# STM32H7P5xx register map
File version: 1.0
Registers are 32-bit, read-write, reset 0x0 unless marked. A register's access mark holds for its fields unless they carry their own. Offsets are from the block's base; [hi:lo] are bit positions.

## DAC1 — Digital to Analog Converter (DAC)
Base 0x48027000
Same registers: DAC2 0x48027400, DAC3 0x48027800, DAC4 0x48027C00
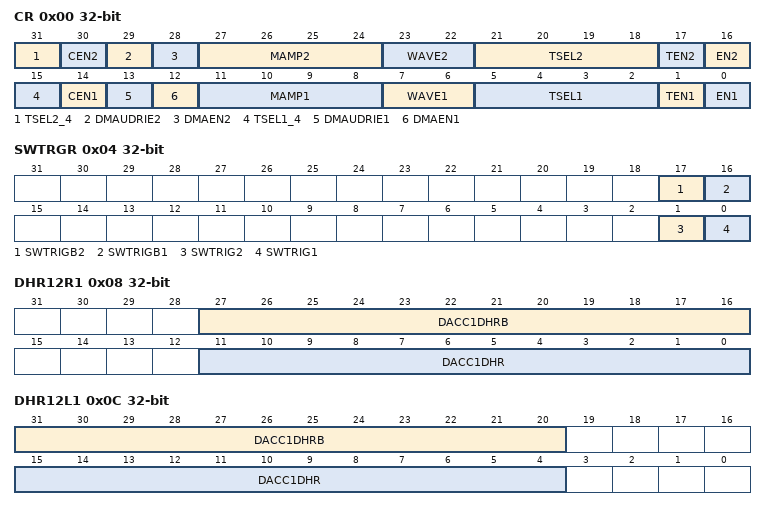
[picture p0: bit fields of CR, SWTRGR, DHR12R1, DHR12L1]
0x00 CR — DAC control register
  [31] TSEL2_4
  [30] CEN2 — DAC channel2 calibration enable
  [29] DMAUDRIE2 — DAC channel2 DMA underrun interrupt enable
  [28] DMAEN2 — DAC channel2 DMA enable
  [27:24] MAMP2 — DAC channel2 mask/amplitude selector
  [23:22] WAVE2 — DAC channel2 noise/triangle wave generation enable
  [21:18] TSEL2 — TSEL2[3:0]: DAC channel2 trigger selection
  [17] TEN2 — DAC channel2 trigger enable
  [16] EN2 — DAC channel2 enable
  [15] TSEL1_4
  [14] CEN1 — DAC channel1 calibration enable
  [13] DMAUDRIE1 — DAC channel1 DMA Underrun Interrupt enable
  [12] DMAEN1 — DAC channel1 DMA enable
  [11:8] MAMP1 — DAC channel1 mask/amplitude selector
  [7:6] WAVE1 — DAC channel1 noise/triangle wave generation enable
  [5:2] TSEL1 — TSEL1[3:0]: DAC channel1 trigger selection
  [1] TEN1 — DAC channel1 trigger enable
  [0] EN1 — DAC channel1 enable
0x04 SWTRGR — DAC software trigger register
  [17] SWTRIGB2 — DAC channel2 software trigger B
  [16] SWTRIGB1 — DAC channel1 software trigger B
  [1] SWTRIG2 — DAC channel2 software trigger
  [0] SWTRIG1 — DAC channel1 software trigger
0x08 DHR12R1 — DAC channel1 12-bit right-aligned data holding register
  [27:16] DACC1DHRB — DAC channel1 12-bit right-aligned data B
  [11:0] DACC1DHR — DAC channel1 12-bit right-aligned data
0x0C DHR12L1 — DAC channel1 12-bit left aligned data holding register
  [31:20] DACC1DHRB — DAC channel1 12-bit left-aligned data B
  [15:4] DACC1DHR — DAC channel1 12-bit left-aligned data
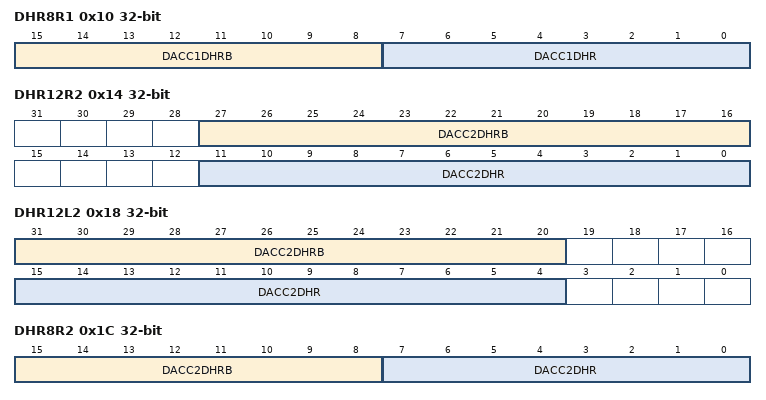
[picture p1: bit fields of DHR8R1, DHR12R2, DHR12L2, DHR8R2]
0x10 DHR8R1 — DAC channel1 8-bit right aligned data holding register
  [15:8] DACC1DHRB — DAC channel1 8-bit right-aligned data
  [7:0] DACC1DHR — DAC channel1 8-bit right-aligned data
0x14 DHR12R2 — DAC channel2 12-bit right aligned data holding register
  [27:16] DACC2DHRB — DAC channel2 12-bit right-aligned data
  [11:0] DACC2DHR — DAC channel2 12-bit right-aligned data
0x18 DHR12L2 — DAC channel2 12-bit left aligned data holding register
  [31:20] DACC2DHRB — DAC channel2 12-bit left-aligned data B
  [15:4] DACC2DHR — DAC channel2 12-bit left-aligned data
0x1C DHR8R2 — DAC channel2 8-bit right-aligned data holding register
  [15:8] DACC2DHRB — DAC channel2 8-bit right-aligned data
  [7:0] DACC2DHR — DAC channel2 8-bit right-aligned data
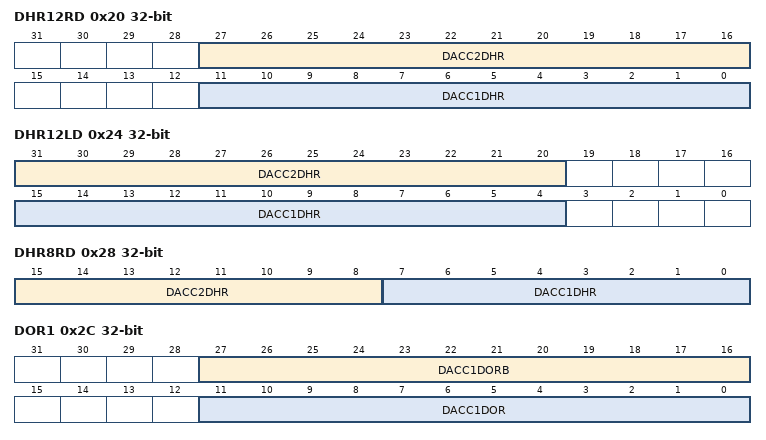
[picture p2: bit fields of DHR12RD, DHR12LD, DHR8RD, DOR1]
0x20 DHR12RD — Dual DAC 12-bit right-aligned data holding register
  [27:16] DACC2DHR — DAC channel2 12-bit right-aligned data
  [11:0] DACC1DHR — DAC channel1 12-bit right-aligned data
0x24 DHR12LD — Dual DAC 12-bit left aligned data holding register
  [31:20] DACC2DHR — DAC channel2 12-bit left-aligned data
  [15:4] DACC1DHR — DAC channel1 12-bit left-aligned data
0x28 DHR8RD — Dual DAC 8-bit right aligned data holding register
  [15:8] DACC2DHR — DAC channel2 8-bit right-aligned data
  [7:0] DACC1DHR — DAC channel1 8-bit right-aligned data
0x2C DOR1 ro — DAC channel1 data output register
  [27:16] DACC1DORB — DAC channel1 data output
  [11:0] DACC1DOR — DAC channel1 data output
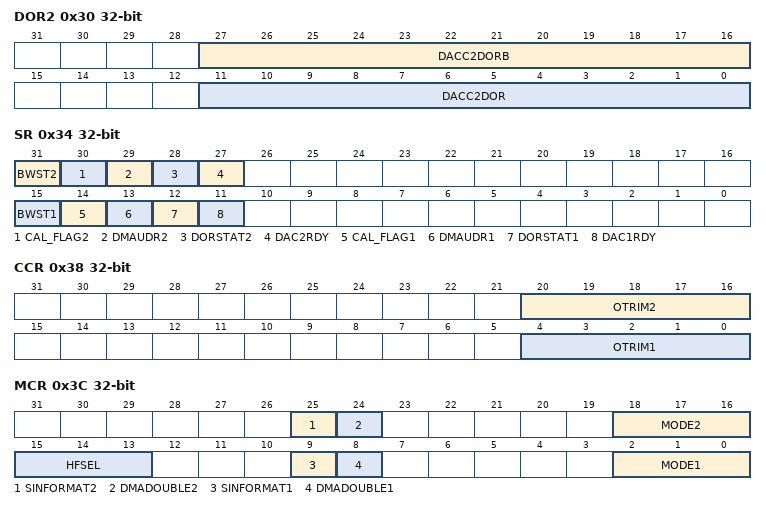
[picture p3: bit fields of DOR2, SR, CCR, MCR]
0x30 DOR2 ro — DAC channel2 data output register
  [27:16] DACC2DORB — DAC channel2 data output
  [11:0] DACC2DOR — DAC channel2 data output
0x34 SR — DAC status register
  [31] BWST2 — DAC channel2 busy writing sample time flag
  [30] CAL_FLAG2 — DAC channel2 calibration offset status
  [29] DMAUDR2 — DAC channel2 DMA underrun flag
  [28] DORSTAT2 — DAC channel2 output register status bit
  [27] DAC2RDY — DAC channel2 ready status bit
  [15] BWST1 — DAC channel1 busy writing sample time flag
  [14] CAL_FLAG1 — DAC channel1 calibration offset status
  [13] DMAUDR1 — DAC channel1 DMA underrun flag
  [12] DORSTAT1 — DAC channel1 output register status bit
  [11] DAC1RDY — DAC channel1 ready status bit
0x38 CCR — DAC calibration control register
  [20:16] OTRIM2 — DAC channel2 offset trimming value
  [4:0] OTRIM1 — DAC channel1 offset trimming value
0x3C MCR — DAC mode control register
  [25] SINFORMAT2 — Enable signed format for DAC channel2
  [24] DMADOUBLE2 — DAC channel2 DMA double data mode
  [18:16] MODE2 — DAC channel2 mode
  [15:13] HFSEL — High frequency interface mode selection
  [9] SINFORMAT1 — Enable signed format for DAC channel1
  [8] DMADOUBLE1 — DAC channel1 DMA double data mode
  [2:0] MODE1 — DAC channel1 mode
0x40 SHSR1 — DAC channel1 sample and hold sample time register
  [9:0] TSAMPLE1 — DAC channel1 sample time (only valid in sample and hold mode)
0x44 SHSR2 — DAC channel2 sample and hold sample time register
  [9:0] TSAMPLE2 — DAC channel2 sample time (only valid in sample and hold mode)
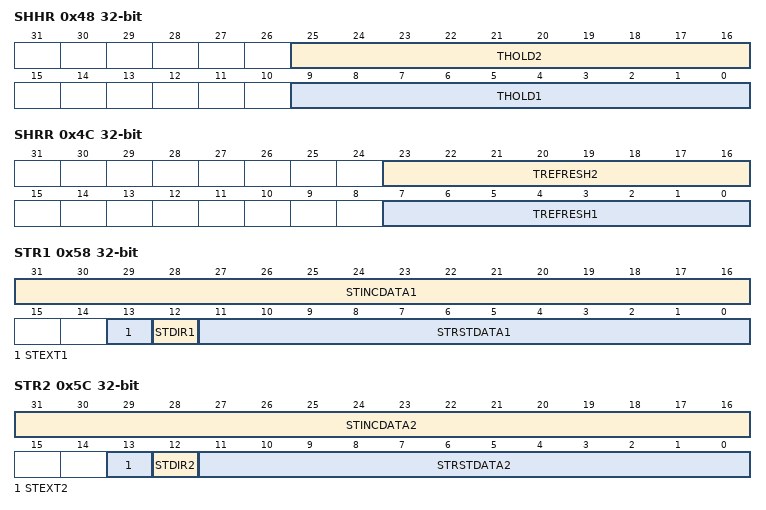
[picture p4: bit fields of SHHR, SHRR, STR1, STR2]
0x48 SHHR — DAC sample and hold time register
  [25:16] THOLD2 — DAC channel2 hold time (only valid in sample and hold mode)
  [9:0] THOLD1 — DAC channel1 hold time (only valid in sample and hold mode)
0x4C SHRR — DAC sample and hold refresh time register
  [23:16] TREFRESH2 — DAC channel2 refresh time (only valid in sample and hold mode)
  [7:0] TREFRESH1 — DAC channel1 refresh time (only valid in sample and hold mode)
0x58 STR1 — DAC channel1 sawtooth register
  [31:16] STINCDATA1 — DAC channel1 sawtooth increment value (12.4 bit format)
  [13] STEXT1 — DAC channel1 sawtooth extended setting
  [12] STDIR1 — DAC channel1 sawtooth direction setting
  [11:0] STRSTDATA1 — DAC channel1 sawtooth reset value
0x5C STR2 — DAC channel2 sawtooth register
  [31:16] STINCDATA2 — DAC channel2 Sawtooth increment value (12.4 bit format)
  [13] STEXT2 — DAC channel2 sawtooth extended setting
  [12] STDIR2 — DAC channel2 sawtooth direction setting
  [11:0] STRSTDATA2 — DAC channel2 sawtooth reset value
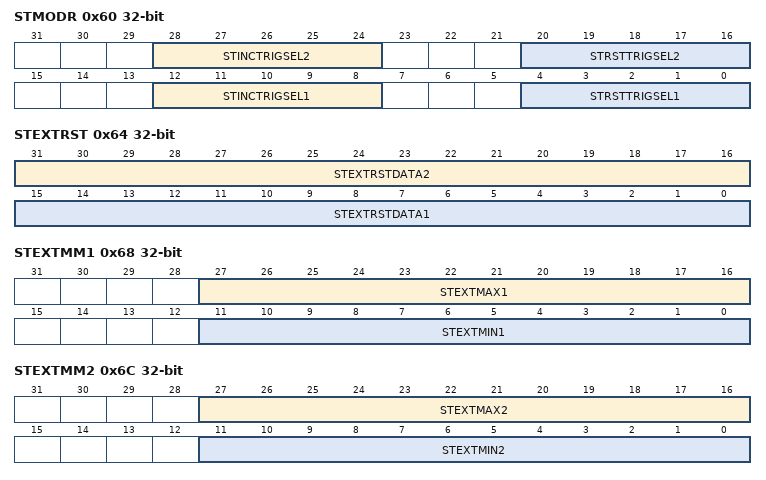
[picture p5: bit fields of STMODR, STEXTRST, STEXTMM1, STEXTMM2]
0x60 STMODR — DAC sawtooth mode register
  [28:24] STINCTRIGSEL2 — DAC channel2 sawtooth increment trigger (STINCTRIG) selection
  [20:16] STRSTTRIGSEL2 — DAC channel2 sawtooth reset trigger (STRSTTRIG) selection
  [12:8] STINCTRIGSEL1 — DAC channel1 sawtooth increment trigger (STINCTRIG) selection
  [4:0] STRSTTRIGSEL1 — DAC channel1 sawtooth reset trigger (STRSTTRIG) selection
0x64 STEXTRST — DAC extended sawtooth reset control register
  [31:16] STEXTRSTDATA2 — DAC channel2 extended sawtooth reset value
  [15:0] STEXTRSTDATA1 — DAC channel1 extended sawtooth reset value
0x68 STEXTMM1 — DAC extended sawtooth minimum and maximum value register
  [27:16] STEXTMAX1 — DAC channel1 extended sawtooth maximum value
  [11:0] STEXTMIN1 — DAC channel1 extended sawtooth minimum value
0x6C STEXTMM2 — DAC extended sawtooth minimum and maximum value register
  [27:16] STEXTMAX2 — DAC channel1 extended sawtooth maximum value
  [11:0] STEXTMIN2 — DAC channel1 extended sawtooth minimum value
0x3EC OR — DAC option register
  [3:0] OP — Option bits
